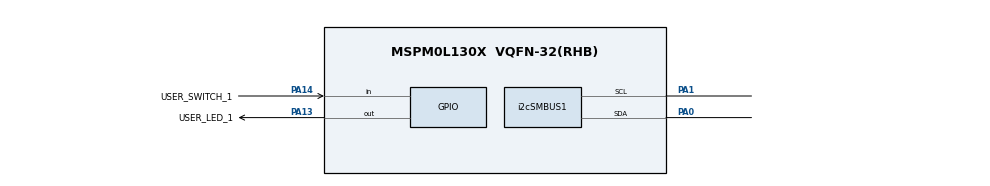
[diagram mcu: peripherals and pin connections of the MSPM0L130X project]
// @cliArgs --device "MSPM0L130X" --package "VQFN-32(RHB)" --part "Default"
// @cliArgs --board /ti/boards/LP_MSPM0L1306 --rtos nortos

/**
 * Import the modules used in this configuration.
 */
const ProjectConfig = scripting.addModule("/ti/project_config/ProjectConfig");
const Board     = scripting.addModule("/ti/driverlib/Board");
const GPIO      = scripting.addModule("/ti/driverlib/GPIO", {}, false);
const GPIO1     = GPIO.addInstance();
const GPIO2     = GPIO.addInstance();
const i2cSMBUS  = scripting.addModule("/ti/driverlib/i2cSMBUS", {}, false);
const i2cSMBUS1 = i2cSMBUS.addInstance();

/**
 * Write custom configuration values to the imported modules.
 */
ProjectConfig.genLibSMBUS     = true;

GPIO1.$name                          = "GPIO_LEDS";
GPIO1.associatedPins[0].$name        = "USER_LED_1";
GPIO1.associatedPins[0].initialValue = "SET";
GPIO1.associatedPins[0].assignedPort = "PORTA";
GPIO1.associatedPins[0].assignedPin  = "13";
GPIO1.associatedPins[0].pin.$assign  = "PA13";

GPIO2.$name                              = "GPIO_SWITCHES";
GPIO2.associatedPins[0].$name            = "USER_SWITCH_1";
GPIO2.associatedPins[0].direction        = "INPUT";
GPIO2.associatedPins[0].internalResistor = "PULL_UP";
GPIO2.associatedPins[0].interruptEn      = true;
GPIO2.associatedPins[0].polarity         = "FALL";
GPIO2.associatedPins[0].assignedPort     = "PORTA";
GPIO2.associatedPins[0].assignedPin      = "14";
GPIO2.associatedPins[0].pin.$assign      = "PA14";

const SYSCTL = scripting.addModule("/ti/driverlib/SYSCTL", {}, false);

i2cSMBUS1.$name                             = "SMB_I2C";
i2cSMBUS1.enableTimeoutA                    = true;
i2cSMBUS1.timeoutACount                     = 255;
i2cSMBUS1.intGeneric                        = ["TIMEOUT_A"];
i2cSMBUS1.basicEnableTarget                 = true;
i2cSMBUS1.advTargetTXEmptyEn                = true;
i2cSMBUS1.basicTargetAddress                = 0x43;
i2cSMBUS1.enableTargetPEC                   = true;
i2cSMBUS1.intTarget                         = ["PEC_RX_ERROR","RXFIFO_TRIGGER","START","STOP","TXFIFO_EMPTY"];
i2cSMBUS1.basicEnableController             = true;
i2cSMBUS1.intController                     = ["ARBITRATION_LOST","NACK","RXFIFO_TRIGGER","STOP"];
i2cSMBUS1.peripheral.$assign                = "I2C0";
i2cSMBUS1.peripheral.sdaPin.$assign         = "PA0";
i2cSMBUS1.peripheral.sclPin.$assign         = "PA1";
i2cSMBUS1.sdaPinConfig.direction            = scripting.forceWrite("OUTPUT");
i2cSMBUS1.sdaPinConfig.hideOutputInversion  = scripting.forceWrite(false);
i2cSMBUS1.sdaPinConfig.onlyInternalResistor = scripting.forceWrite(false);
i2cSMBUS1.sdaPinConfig.passedPeripheralType = scripting.forceWrite("Digital");
i2cSMBUS1.sdaPinConfig.$name                = "ti_driverlib_gpio_GPIOPinGeneric1";
i2cSMBUS1.sclPinConfig.direction            = scripting.forceWrite("OUTPUT");
i2cSMBUS1.sclPinConfig.hideOutputInversion  = scripting.forceWrite(false);
i2cSMBUS1.sclPinConfig.onlyInternalResistor = scripting.forceWrite(false);
i2cSMBUS1.sclPinConfig.passedPeripheralType = scripting.forceWrite("Digital");
i2cSMBUS1.sclPinConfig.$name                = "ti_driverlib_gpio_GPIOPinGeneric2";
